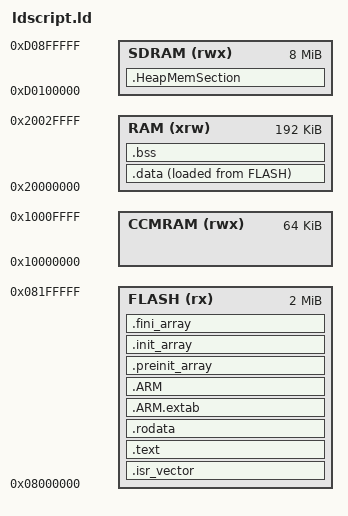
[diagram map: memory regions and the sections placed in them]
/* STM32f429i-Disco-Board */
/* Entry Point */
ENTRY(Reset_Handler)


/* Specify the memory areas */
/* 2MB   FLASH */
/* 256KB RAM */
/* 8MB SDRAM */
/* TBD: section for RAM2, confirm SDRAM entry ! */

MEMORY
{
  FLASH (rx)  : ORIGIN = 0x08000000, LENGTH = 2048K
  RAM (xrw)   : ORIGIN = 0x20000000, LENGTH =  192K
  CCMRAM (rwx): ORIGIN = 0x10000000, LENGTH =   64K
  SDRAM (rwx) : ORIGIN = 0xD0100000, LENGTH =    8M
}

/* Highest address of the user mode stack */
/* _estack = ORIGIN(   RAM) + LENGTH(   RAM); */ /* Stack in normal RAM */
_estack    = ORIGIN(CCMRAM) + LENGTH(CCMRAM);    /* Stack in    CCM RAM */

/* Define output sections */
SECTIONS
{
  /* The startup code goes first into FLASH */
  .isr_vector :
  {
    . = ALIGN(4);
    KEEP(*(.isr_vector)) /* Startup code */
    . = ALIGN(4);
  } >FLASH

  /* The program code and other data goes into FLASH */
  .text :
  {
    . = ALIGN(4);
    *(.text)           /* .text sections (code) */
    *(.text*)          /* .text* sections (code) */
    *(.glue_7)         /* glue arm to thumb code */
    *(.glue_7t)        /* glue thumb to arm code */
    *(.eh_frame)

    KEEP (*(.init))
    KEEP (*(.fini))

    . = ALIGN(4);
    _etext = .;        /* define a global symbols at end of code */
  } >FLASH

  /* Constant data goes into FLASH */
  .rodata ALIGN(4) :
  {
    . = ALIGN(4);
    *(.rodata)         /* .rodata sections (constants, strings, etc.) */
    *(.rodata*)        /* .rodata* sections (constants, strings, etc.) */
    . = ALIGN(4);
  } >FLASH

  .ARM.extab   : { *(.ARM.extab* .gnu.linkonce.armextab.*) } >FLASH
  .ARM : {
    __exidx_start = .;
    *(.ARM.exidx*)
    __exidx_end = .;
  } >FLASH

  .preinit_array     :
  {
    PROVIDE_HIDDEN (__preinit_array_start = .);
    KEEP (*(.preinit_array*))
    PROVIDE_HIDDEN (__preinit_array_end = .);
  } >FLASH
  .init_array :
  {
    PROVIDE_HIDDEN (__init_array_start = .);
    KEEP (*(SORT(.init_array.*)))
    KEEP (*(.init_array*))
    PROVIDE_HIDDEN (__init_array_end = .);
  } >FLASH
  .fini_array :
  {
    PROVIDE_HIDDEN (__fini_array_start = .);
    KEEP (*(SORT(.fini_array.*)))
    KEEP (*(.fini_array*))
    PROVIDE_HIDDEN (__fini_array_end = .);
  } >FLASH

  /* used by the startup to initialize data */
  _sidata = LOADADDR(.data);

  /* Initialized data sections goes into RAM, load LMA copy after code */
  .data :
  {
    . = ALIGN(4);
    _sdata = .;        /* create a global symbol at data start */
    *(.data)           /* .data sections */
    *(.data*)          /* .data* sections */

    . = ALIGN(4);
    _edata = .;        /* define a global symbol at data end */
  } >RAM AT> FLASH

  /* Uninitialized data section */
  . = ALIGN(4);
  .bss :
  {
    /* This is used by the startup in order to initialize the .bss secion */
    _sbss = .;         /* define a global symbol at bss start */
    __bss_start__ = _sbss;
    *(.bss)
    *(.bss*)
    *(COMMON)

    . = ALIGN(4);
    _ebss = .;         /* define a global symbol at bss end */
    __bss_end__ = _ebss;
  } >RAM
  
  . = ALIGN(4); 
  _end = . ; 

  .HeapMemSection : 
  {
      *(.HeapMemSection)
  } > SDRAM

  PROVIDE ( _end = . );
  
  /* Remove information from the standard libraries */
  /DISCARD/ :
  {
    libc.a ( * )
    libm.a ( * )
    libgcc.a ( * )
  }

  .ARM.attributes 0 : { *(.ARM.attributes) }
}
